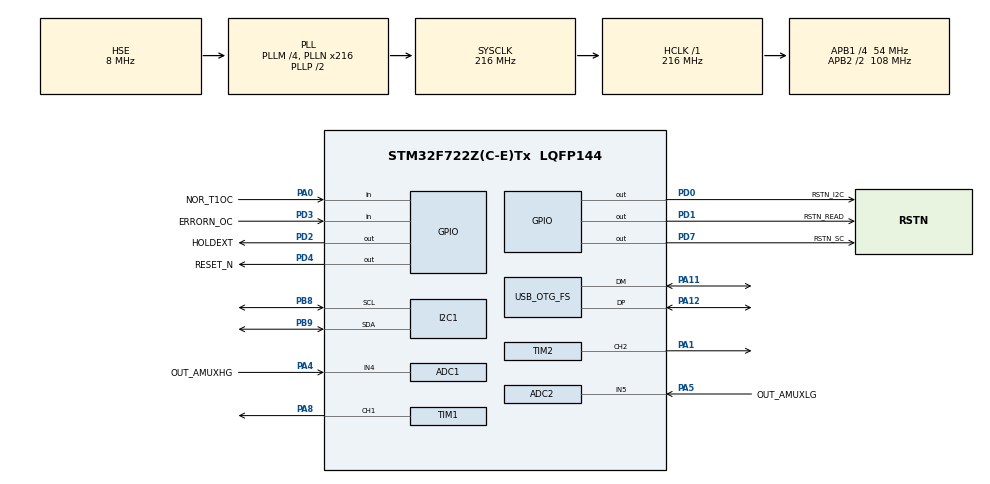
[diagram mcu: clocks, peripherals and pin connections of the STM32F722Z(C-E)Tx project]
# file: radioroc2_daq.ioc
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ADC1.Channel-0\#ChannelRegularConversion=ADC_CHANNEL_4
ADC1.ClockPrescaler=ADC_CLOCK_SYNC_PCLK_DIV6
ADC1.NbrOfConversionFlag=1
ADC1.Rank-0\#ChannelRegularConversion=1
ADC1.SamplingTime-0\#ChannelRegularConversion=ADC_SAMPLETIME_480CYCLES
ADC1.master=1
ADC2.Channel-0\#ChannelRegularConversion=ADC_CHANNEL_5
ADC2.ClockPrescaler=ADC_CLOCK_SYNC_PCLK_DIV6
ADC2.NbrOfConversionFlag=1
ADC2.Rank-0\#ChannelRegularConversion=1
ADC2.SamplingTime-0\#ChannelRegularConversion=ADC_SAMPLETIME_480CYCLES
I2C1.Timing=0x20404768
Mcu.Family=STM32F7
Mcu.Name=STM32F722Z(C-E)Tx
Mcu.Package=LQFP144
NVIC.EXTI0_IRQn=true\:2\:0\:true\:false\:true\:true\:true\:true
NVIC.I2C1_EV_IRQn=true\:4\:0\:true\:false\:true\:true\:true\:true
NVIC.OTG_FS_IRQn=true\:3\:0\:true\:false\:true\:true\:true\:true
NVIC.PriorityGroup=NVIC_PRIORITYGROUP_4
NVIC.TIM1_BRK_TIM9_IRQn=true\:5\:0\:true\:false\:true\:true\:true\:true
NVIC.TIM1_CC_IRQn=true\:5\:0\:true\:false\:true\:true\:true\:true
NVIC.TIM1_TRG_COM_TIM11_IRQn=true\:5\:0\:true\:false\:true\:true\:true\:true
NVIC.TIM1_UP_TIM10_IRQn=true\:5\:0\:true\:false\:true\:true\:true\:true
NVIC.TIM2_IRQn=true\:5\:0\:true\:false\:true\:true\:true\:true
PA0-WKUP.GPIO_Label=NOR_T1OC
PA0-WKUP.GPIO_ModeDefaultEXTI=GPIO_MODE_IT_FALLING
PA0-WKUP.GPIO_PuPd=GPIO_PULLUP
PA0-WKUP.Signal=SharedStack_PA0
PA0-WKUP.Stacked=true
PA1.Signal=S_TIM2_CH2
PA11.Mode=Device_Only
PA11.Signal=USB_OTG_FS_DM
PA12.Mode=Device_Only
PA12.Signal=USB_OTG_FS_DP
PA4.GPIO_Label=OUT_AMUXHG
PA4.Signal=ADCx_IN4
PA5.GPIO_Label=OUT_AMUXLG
PA5.Signal=ADCx_IN5
PA8.Signal=S_TIM1_CH1
PB8.Mode=I2C
PB8.Signal=I2C1_SCL
PB9.Mode=I2C
PB9.Signal=I2C1_SDA
PD0.GPIO_Label=RSTN_I2C
PD0.GPIO_Speed=GPIO_SPEED_FREQ_HIGH
PD0.PinState=GPIO_PIN_SET
PD0.Signal=GPIO_Output
PD1.GPIO_Label=RSTN_READ
PD1.GPIO_Speed=GPIO_SPEED_FREQ_HIGH
PD1.PinState=GPIO_PIN_SET
PD1.Signal=GPIO_Output
PD2.GPIO_Label=HOLDEXT
PD2.GPIO_Speed=GPIO_SPEED_FREQ_HIGH
PD2.PinState=GPIO_PIN_RESET
PD2.Signal=GPIO_Output
PD3.GPIO_Label=ERRORN_OC
PD3.GPIO_PuPd=GPIO_PULLUP
PD3.Signal=GPIO_Input
PD4.GPIO_Label=RESET_N
PD4.GPIO_Speed=GPIO_SPEED_FREQ_HIGH
PD4.PinState=GPIO_PIN_SET
PD4.Signal=GPIO_Output
PD7.GPIO_Label=RSTN_SC
PD7.GPIO_Speed=GPIO_SPEED_FREQ_HIGH
PD7.PinState=GPIO_PIN_SET
PD7.Signal=GPIO_Output
PH0-OSC_IN.Mode=HSE-External-Oscillator
PH0-OSC_IN.Signal=RCC_OSC_IN
PH1-OSC_OUT.Mode=HSE-External-Oscillator
PH1-OSC_OUT.Signal=RCC_OSC_OUT
ProjectManager.HeapSize=0x200
ProjectManager.StackSize=0x400
ProjectManager.TargetToolchain=STM32CubeIDE
RCC.AHBFreq_Value=216000000
RCC.APB1CLKDivider=RCC_HCLK_DIV4
RCC.APB1Freq_Value=54000000
RCC.APB1TimFreq_Value=108000000
RCC.APB2CLKDivider=RCC_HCLK_DIV2
RCC.APB2Freq_Value=108000000
RCC.APB2TimFreq_Value=216000000
RCC.CortexFreq_Value=216000000
RCC.HCLKFreq_Value=216000000
RCC.HSE_VALUE=8000000
RCC.PLLM=4
RCC.PLLN=216
RCC.SYSCLKFreq_VALUE=216000000
RCC.SYSCLKSource=RCC_SYSCLKSOURCE_PLLCLK
RCC.USBFreq_Value=48000000
RCC.VCOOutputFreq_Value=432000000
SH.ADCx_IN4.0=ADC1_IN4,IN4
SH.ADCx_IN5.0=ADC2_IN5,IN5
SH.S_TIM1_CH1.0=TIM1_CH1,PWM Generation1 CH1
SH.S_TIM2_CH2.0=TIM2_CH2,PWM Generation2 CH2
SH.SharedStack_PA0.0=GPIO_Input+0
SH.SharedStack_PA0.1=GPIO_EXTI0
TIM1.AutoReloadPreload=TIM_AUTORELOAD_PRELOAD_ENABLE
TIM1.Channel-PWM\ Generation1\ CH1=TIM_CHANNEL_1
TIM1.Period=107
TIM1.Pulse-PWM\ Generation1\ CH1=53
TIM2.AutoReloadPreload=TIM_AUTORELOAD_PRELOAD_ENABLE
TIM2.Channel-PWM\ Generation2\ CH2=TIM_CHANNEL_2
TIM2.Period=29
TIM2.Prescaler=215
TIM2.Pulse-PWM\ Generation2\ CH2=14
USB_DEVICE.CLASS_NAME_FS=CDC
USB_DEVICE.VirtualMode-CDC_FS=Cdc
USB_DEVICE.VirtualModeFS=Cdc_FS
USB_OTG_FS.VirtualMode=Device_Only
VP_TIM1_VS_ClockSourceINT.Mode=Internal
VP_TIM2_VS_ClockSourceINT.Mode=Internal
VP_TIM2_VS_OPM.Mode=OPM_bit
VP_USB_DEVICE_VS_USB_DEVICE_CDC_FS.Mode=CDC_FS
board=NUCLEO-F722ZE

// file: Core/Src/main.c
/* USER CODE BEGIN Header */
/**
  ******************************************************************************
  * @file           : main.c
  * @brief          : Main program body
  ******************************************************************************
  * @attention
  *
  * Copyright (c) 2026 STMicroelectronics.
  * All rights reserved.
  *
  * This software is licensed under terms that can be found in the LICENSE file
  * in the root directory of this software component.
  * If no LICENSE file comes with this software, it is provided AS-IS.
  *
  ******************************************************************************
  */
/* USER CODE END Header */
#include "main.h"
#include "usb_device.h"

/* USER CODE BEGIN Includes */
#include "config.h"
#include "channel_map.h"
#include "radioroc2_i2c.h"
#include "system_init.h"
#include "timers.h"
#include "daq.h"
#include "compensation.h"
#include "usb_comm.h"
#include "main_app.h"
/* USER CODE END Includes */

ADC_HandleTypeDef hadc1;
ADC_HandleTypeDef hadc2;

I2C_HandleTypeDef hi2c1;

TIM_HandleTypeDef htim1;
TIM_HandleTypeDef htim2;
TIM_HandleTypeDef htim3;   /* 1-second tick — configured by timers_start_1s_tick() */

void SystemClock_Config(void);
static void MX_GPIO_Init(void);
static void MX_ADC1_Init(void);
static void MX_ADC2_Init(void);
static void MX_I2C1_Init(void);
static void MX_TIM1_Init(void);
static void MX_TIM2_Init(void);

int main(void)
{

  /* MCU Configuration--------------------------------------------------------*/

  /* Reset of all peripherals, Initializes the Flash interface and the Systick. */
  HAL_Init();

  /* Configure the system clock */
  SystemClock_Config();

  /* Initialize all configured peripherals */
  MX_GPIO_Init();
  MX_ADC1_Init();
  MX_ADC2_Init();
  MX_I2C1_Init();
  MX_TIM1_Init();
  MX_TIM2_Init();
  MX_USB_DEVICE_Init();
  /* USER CODE BEGIN 2 */
  app_init();
  /* USER CODE END 2 */

  /* Infinite loop */
  /* USER CODE BEGIN WHILE */
  app_run();   /* does not return — contains the infinite loop */
  while (1)
  {
    /* USER CODE END WHILE */

  }
}

void SystemClock_Config(void)
{
  RCC_OscInitTypeDef RCC_OscInitStruct = {0};
  RCC_ClkInitTypeDef RCC_ClkInitStruct = {0};

  /** Configure the main internal regulator output voltage
  */
  __HAL_RCC_PWR_CLK_ENABLE();
  __HAL_PWR_VOLTAGESCALING_CONFIG(PWR_REGULATOR_VOLTAGE_SCALE1);

  /** Initializes the RCC Oscillators according to the specified parameters
  * in the RCC_OscInitTypeDef structure.
  */
  RCC_OscInitStruct.OscillatorType = RCC_OSCILLATORTYPE_HSE;
  RCC_OscInitStruct.HSEState = RCC_HSE_ON;
  RCC_OscInitStruct.PLL.PLLState = RCC_PLL_ON;
  RCC_OscInitStruct.PLL.PLLSource = RCC_PLLSOURCE_HSE;
  RCC_OscInitStruct.PLL.PLLM = 4;
  RCC_OscInitStruct.PLL.PLLN = 216;
  RCC_OscInitStruct.PLL.PLLP = RCC_PLLP_DIV2;
  RCC_OscInitStruct.PLL.PLLQ = 2;
  if (HAL_RCC_OscConfig(&RCC_OscInitStruct) != HAL_OK)
  {
    Error_Handler();
  }

  /** Activate the Over-Drive mode
  */
  if (HAL_PWREx_EnableOverDrive() != HAL_OK)
  {
    Error_Handler();
  }

  /** Initializes the CPU, AHB and APB buses clocks
  */
  RCC_ClkInitStruct.ClockType = RCC_CLOCKTYPE_HCLK|RCC_CLOCKTYPE_SYSCLK
                              |RCC_CLOCKTYPE_PCLK1|RCC_CLOCKTYPE_PCLK2;
  RCC_ClkInitStruct.SYSCLKSource = RCC_SYSCLKSOURCE_PLLCLK;
  RCC_ClkInitStruct.AHBCLKDivider = RCC_SYSCLK_DIV1;
  RCC_ClkInitStruct.APB1CLKDivider = RCC_HCLK_DIV4;
  RCC_ClkInitStruct.APB2CLKDivider = RCC_HCLK_DIV2;

  if (HAL_RCC_ClockConfig(&RCC_ClkInitStruct, FLASH_LATENCY_7) != HAL_OK)
  {
    Error_Handler();
  }
}

static void MX_ADC1_Init(void)
{

  ADC_ChannelConfTypeDef sConfig = {0};

  /** Configure the global features of the ADC (Clock, Resolution, Data Alignment and number of conversion)
  */
  hadc1.Instance = ADC1;
  hadc1.Init.ClockPrescaler = ADC_CLOCK_SYNC_PCLK_DIV6;
  hadc1.Init.Resolution = ADC_RESOLUTION_12B;
  hadc1.Init.ScanConvMode = ADC_SCAN_DISABLE;
  hadc1.Init.ContinuousConvMode = DISABLE;
  hadc1.Init.DiscontinuousConvMode = DISABLE;
  hadc1.Init.ExternalTrigConvEdge = ADC_EXTERNALTRIGCONVEDGE_NONE;
  hadc1.Init.ExternalTrigConv = ADC_SOFTWARE_START;
  hadc1.Init.DataAlign = ADC_DATAALIGN_RIGHT;
  hadc1.Init.NbrOfConversion = 1;
  hadc1.Init.DMAContinuousRequests = DISABLE;
  hadc1.Init.EOCSelection = ADC_EOC_SINGLE_CONV;
  if (HAL_ADC_Init(&hadc1) != HAL_OK)
  {
    Error_Handler();
  }

  /** Configure for the selected ADC regular channel its corresponding rank in the sequencer and its sample time.
  */
  sConfig.Channel = ADC_CHANNEL_4;
  sConfig.Rank = ADC_REGULAR_RANK_1;
  sConfig.SamplingTime = ADC_SAMPLETIME_480CYCLES;
  if (HAL_ADC_ConfigChannel(&hadc1, &sConfig) != HAL_OK)
  {
    Error_Handler();
  }

}

static void MX_ADC2_Init(void)
{

  ADC_ChannelConfTypeDef sConfig = {0};

  /** Configure the global features of the ADC (Clock, Resolution, Data Alignment and number of conversion)
  */
  hadc2.Instance = ADC2;
  hadc2.Init.ClockPrescaler = ADC_CLOCK_SYNC_PCLK_DIV6;
  hadc2.Init.Resolution = ADC_RESOLUTION_12B;
  hadc2.Init.ScanConvMode = ADC_SCAN_DISABLE;
  hadc2.Init.ContinuousConvMode = DISABLE;
  hadc2.Init.DiscontinuousConvMode = DISABLE;
  hadc2.Init.ExternalTrigConvEdge = ADC_EXTERNALTRIGCONVEDGE_NONE;
  hadc2.Init.ExternalTrigConv = ADC_SOFTWARE_START;
  hadc2.Init.DataAlign = ADC_DATAALIGN_RIGHT;
  hadc2.Init.NbrOfConversion = 1;
  hadc2.Init.DMAContinuousRequests = DISABLE;
  hadc2.Init.EOCSelection = ADC_EOC_SINGLE_CONV;
  if (HAL_ADC_Init(&hadc2) != HAL_OK)
  {
    Error_Handler();
  }

  /** Configure for the selected ADC regular channel its corresponding rank in the sequencer and its sample time.
  */
  sConfig.Channel = ADC_CHANNEL_5;
  sConfig.Rank = ADC_REGULAR_RANK_1;
  sConfig.SamplingTime = ADC_SAMPLETIME_480CYCLES;
  if (HAL_ADC_ConfigChannel(&hadc2, &sConfig) != HAL_OK)
  {
    Error_Handler();
  }

}

static void MX_I2C1_Init(void)
{

  hi2c1.Instance = I2C1;
  hi2c1.Init.Timing = 0x20404768;
  hi2c1.Init.OwnAddress1 = 0;
  hi2c1.Init.AddressingMode = I2C_ADDRESSINGMODE_7BIT;
  hi2c1.Init.DualAddressMode = I2C_DUALADDRESS_DISABLE;
  hi2c1.Init.OwnAddress2 = 0;
  hi2c1.Init.OwnAddress2Masks = I2C_OA2_NOMASK;
  hi2c1.Init.GeneralCallMode = I2C_GENERALCALL_DISABLE;
  hi2c1.Init.NoStretchMode = I2C_NOSTRETCH_DISABLE;
  if (HAL_I2C_Init(&hi2c1) != HAL_OK)
  {
    Error_Handler();
  }

  /** Configure Analogue filter
  */
  if (HAL_I2CEx_ConfigAnalogFilter(&hi2c1, I2C_ANALOGFILTER_ENABLE) != HAL_OK)
  {
    Error_Handler();
  }

  /** Configure Digital filter
  */
  if (HAL_I2CEx_ConfigDigitalFilter(&hi2c1, 0) != HAL_OK)
  {
    Error_Handler();
  }

}

static void MX_TIM1_Init(void)
{

  TIM_ClockConfigTypeDef sClockSourceConfig = {0};
  TIM_MasterConfigTypeDef sMasterConfig = {0};
  TIM_OC_InitTypeDef sConfigOC = {0};
  TIM_BreakDeadTimeConfigTypeDef sBreakDeadTimeConfig = {0};

  htim1.Instance = TIM1;
  htim1.Init.Prescaler = 0;
  htim1.Init.CounterMode = TIM_COUNTERMODE_UP;
  htim1.Init.Period = 107;
  htim1.Init.ClockDivision = TIM_CLOCKDIVISION_DIV1;
  htim1.Init.RepetitionCounter = 0;
  htim1.Init.AutoReloadPreload = TIM_AUTORELOAD_PRELOAD_ENABLE;
  if (HAL_TIM_Base_Init(&htim1) != HAL_OK)
  {
    Error_Handler();
  }
  sClockSourceConfig.ClockSource = TIM_CLOCKSOURCE_INTERNAL;
  if (HAL_TIM_ConfigClockSource(&htim1, &sClockSourceConfig) != HAL_OK)
  {
    Error_Handler();
  }
  if (HAL_TIM_PWM_Init(&htim1) != HAL_OK)
  {
    Error_Handler();
  }
  sMasterConfig.MasterOutputTrigger = TIM_TRGO_RESET;
  sMasterConfig.MasterOutputTrigger2 = TIM_TRGO2_RESET;
  sMasterConfig.MasterSlaveMode = TIM_MASTERSLAVEMODE_DISABLE;
  if (HAL_TIMEx_MasterConfigSynchronization(&htim1, &sMasterConfig) != HAL_OK)
  {
    Error_Handler();
  }
  sConfigOC.OCMode = TIM_OCMODE_PWM1;
  sConfigOC.Pulse = 53;
  sConfigOC.OCPolarity = TIM_OCPOLARITY_HIGH;
  sConfigOC.OCNPolarity = TIM_OCNPOLARITY_HIGH;
  sConfigOC.OCFastMode = TIM_OCFAST_DISABLE;
  sConfigOC.OCIdleState = TIM_OCIDLESTATE_RESET;
  sConfigOC.OCNIdleState = TIM_OCNIDLESTATE_RESET;
  if (HAL_TIM_PWM_ConfigChannel(&htim1, &sConfigOC, TIM_CHANNEL_1) != HAL_OK)
  {
    Error_Handler();
  }
  sBreakDeadTimeConfig.OffStateRunMode = TIM_OSSR_DISABLE;
  sBreakDeadTimeConfig.OffStateIDLEMode = TIM_OSSI_DISABLE;
  sBreakDeadTimeConfig.LockLevel = TIM_LOCKLEVEL_OFF;
  sBreakDeadTimeConfig.DeadTime = 0;
  sBreakDeadTimeConfig.BreakState = TIM_BREAK_DISABLE;
  sBreakDeadTimeConfig.BreakPolarity = TIM_BREAKPOLARITY_HIGH;
  sBreakDeadTimeConfig.BreakFilter = 0;
  sBreakDeadTimeConfig.Break2State = TIM_BREAK2_DISABLE;
  sBreakDeadTimeConfig.Break2Polarity = TIM_BREAK2POLARITY_HIGH;
  sBreakDeadTimeConfig.Break2Filter = 0;
  sBreakDeadTimeConfig.AutomaticOutput = TIM_AUTOMATICOUTPUT_DISABLE;
  if (HAL_TIMEx_ConfigBreakDeadTime(&htim1, &sBreakDeadTimeConfig) != HAL_OK)
  {
    Error_Handler();
  }
  HAL_TIM_MspPostInit(&htim1);

}

static void MX_TIM2_Init(void)
{

  TIM_ClockConfigTypeDef sClockSourceConfig = {0};
  TIM_MasterConfigTypeDef sMasterConfig = {0};
  TIM_OC_InitTypeDef sConfigOC = {0};

  htim2.Instance = TIM2;
  htim2.Init.Prescaler = 215;
  htim2.Init.CounterMode = TIM_COUNTERMODE_UP;
  htim2.Init.Period = 29;
  htim2.Init.ClockDivision = TIM_CLOCKDIVISION_DIV1;
  htim2.Init.AutoReloadPreload = TIM_AUTORELOAD_PRELOAD_ENABLE;
  if (HAL_TIM_Base_Init(&htim2) != HAL_OK)
  {
    Error_Handler();
  }
  sClockSourceConfig.ClockSource = TIM_CLOCKSOURCE_INTERNAL;
  if (HAL_TIM_ConfigClockSource(&htim2, &sClockSourceConfig) != HAL_OK)
  {
    Error_Handler();
  }
  if (HAL_TIM_PWM_Init(&htim2) != HAL_OK)
  {
    Error_Handler();
  }
  if (HAL_TIM_OnePulse_Init(&htim2, TIM_OPMODE_SINGLE) != HAL_OK)
  {
    Error_Handler();
  }
  sMasterConfig.MasterOutputTrigger = TIM_TRGO_RESET;
  sMasterConfig.MasterSlaveMode = TIM_MASTERSLAVEMODE_DISABLE;
  if (HAL_TIMEx_MasterConfigSynchronization(&htim2, &sMasterConfig) != HAL_OK)
  {
    Error_Handler();
  }
  sConfigOC.OCMode = TIM_OCMODE_PWM1;
  sConfigOC.Pulse = 14;
  sConfigOC.OCPolarity = TIM_OCPOLARITY_HIGH;
  sConfigOC.OCFastMode = TIM_OCFAST_DISABLE;
  if (HAL_TIM_PWM_ConfigChannel(&htim2, &sConfigOC, TIM_CHANNEL_2) != HAL_OK)
  {
    Error_Handler();
  }
  HAL_TIM_MspPostInit(&htim2);

}

static void MX_GPIO_Init(void)
{
  GPIO_InitTypeDef GPIO_InitStruct = {0};

  /* GPIO Ports Clock Enable */
  __HAL_RCC_GPIOH_CLK_ENABLE();
  __HAL_RCC_GPIOA_CLK_ENABLE();
  __HAL_RCC_GPIOD_CLK_ENABLE();
  __HAL_RCC_GPIOB_CLK_ENABLE();

  /*Configure GPIO pin Output Level */
  HAL_GPIO_WritePin(GPIOD, RSTN_I2C_Pin|RSTN_READ_Pin|RESET_N_Pin|RSTN_SC_Pin, GPIO_PIN_SET);

  /*Configure GPIO pin Output Level */
  HAL_GPIO_WritePin(HOLDEXT_GPIO_Port, HOLDEXT_Pin, GPIO_PIN_RESET);

  /*Configure GPIO pin : NOR_T1OC_Pin */
  GPIO_InitStruct.Pin = NOR_T1OC_Pin;
  GPIO_InitStruct.Mode = GPIO_MODE_IT_FALLING;
  GPIO_InitStruct.Pull = GPIO_PULLUP;
  HAL_GPIO_Init(NOR_T1OC_GPIO_Port, &GPIO_InitStruct);

  /*Configure GPIO pins : RSTN_I2C_Pin RSTN_READ_Pin HOLDEXT_Pin RESET_N_Pin
                           RSTN_SC_Pin */
  GPIO_InitStruct.Pin = RSTN_I2C_Pin|RSTN_READ_Pin|HOLDEXT_Pin|RESET_N_Pin
                          |RSTN_SC_Pin;
  GPIO_InitStruct.Mode = GPIO_MODE_OUTPUT_PP;
  GPIO_InitStruct.Pull = GPIO_NOPULL;
  GPIO_InitStruct.Speed = GPIO_SPEED_FREQ_HIGH;
  HAL_GPIO_Init(GPIOD, &GPIO_InitStruct);

  /*Configure GPIO pin : ERRORN_OC_Pin */
  GPIO_InitStruct.Pin = ERRORN_OC_Pin;
  GPIO_InitStruct.Mode = GPIO_MODE_INPUT;
  GPIO_InitStruct.Pull = GPIO_PULLUP;
  HAL_GPIO_Init(ERRORN_OC_GPIO_Port, &GPIO_InitStruct);

  /* EXTI interrupt init*/
  HAL_NVIC_SetPriority(EXTI0_IRQn, 2, 0);
  HAL_NVIC_EnableIRQ(EXTI0_IRQn);

}

/* USER CODE BEGIN 4 */

/**
 * @brief  TIM period elapsed callback.
 *         Handles TIM3 (1-second tick for temperature / DAC update).
 *         SysTick_Handler in stm32f7xx_it.c calls HAL_IncTick() —
 *         do NOT add an HAL_IncTick() call here for TIM1.
 */
void HAL_TIM_PeriodElapsedCallback(TIM_HandleTypeDef *htim)
{
  if (htim->Instance == TIM3)
  {
    timers_on_tim3_elapsed();   /* sets 1-second flag for main loop */
  }
}

/* NOTE: EXTI0_IRQHandler is defined in stm32f7xx_it.c.
 *       It calls daq_exti0_irq_handler() to set g_event_pending. */

/* USER CODE END 4 */

void Error_Handler(void)
{
  __disable_irq();
  while (1)
  {
  }
}
